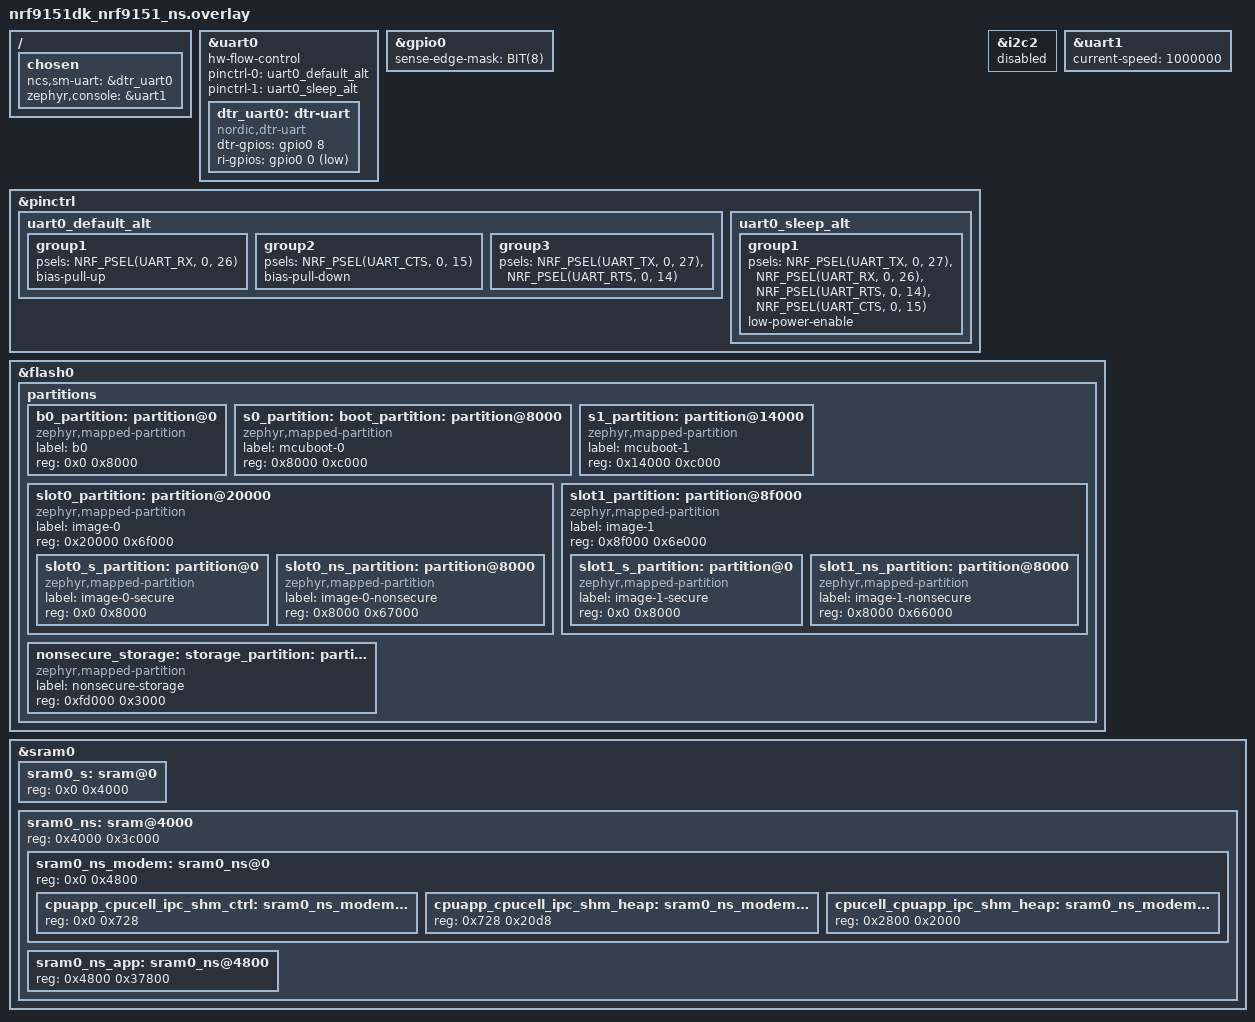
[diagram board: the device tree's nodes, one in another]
/*
 * Copyright (c) 2024 Nordic Semiconductor ASA
 *
 * SPDX-License-Identifier: LicenseRef-Nordic-5-Clause
 */

/ {
	chosen {
		ncs,sm-uart = &dtr_uart0;
		zephyr,console = &uart1;
	};
};

/* DTR with DK */
&uart0 {
	status = "okay";
	hw-flow-control;

	dtr_uart0: dtr-uart {
		compatible = "nordic,dtr-uart";
		dtr-gpios = <&gpio0 8 (GPIO_PULL_UP | GPIO_ACTIVE_HIGH)>;
		ri-gpios = <&gpio0 0 GPIO_ACTIVE_LOW>;
		status = "okay";
	};
	pinctrl-0 = <&uart0_default_alt>;
	pinctrl-1 = <&uart0_sleep_alt>;
	pinctrl-names = "default", "sleep";

};

&gpio0 {
	status = "okay";
	/* Use PORT event for DTR (8) pin to save power */
	sense-edge-mask = <BIT(8)>;
};


&pinctrl {
	uart0_default_alt: uart0_default_alt {
		group1 {
			psels = <NRF_PSEL(UART_RX, 0, 26)>;
			bias-pull-up;
		};
		group2 {
			psels = <NRF_PSEL(UART_CTS, 0, 15)>;
			bias-pull-down;
		};
		group3 {
			psels = <NRF_PSEL(UART_TX, 0, 27)>,
				<NRF_PSEL(UART_RTS, 0, 14)>;
		};
	};

	uart0_sleep_alt: uart0_sleep_alt {
		group1 {
			psels = <NRF_PSEL(UART_TX, 0, 27)>,
				<NRF_PSEL(UART_RX, 0, 26)>,
				<NRF_PSEL(UART_RTS, 0, 14)>,
				<NRF_PSEL(UART_CTS, 0, 15)>;
			low-power-enable;
		};
	};
};

/* Disable I2C2.
 * - Enabling IO expander causes ~20uA to be consumed while DTR is deasserted.
 * - We use P0.31 and P0.30 pins for DTR and RI signals with external MCU.
 */
&i2c2 {
	status = "disabled";
};

/* Enable UART1 as the shared backend for Zephyr logs and modem traces (VCOM1 on the DK).
 * Modem traces require 1 000 000 baud. Hardware flow control is not used.
 */
&uart1 {
	status = "okay";
	current-speed = <1000000>;
};

/*
 * Flash partition layout for nRF9151 DK (same with B0, MCUboot and application):
 *
 * 0x0000_0000  b0 (NSIB)                    ( 32 kB)
 * 0x0000_8000  s0 (MCUBoot image, slot 0)   ( 48 kB)
 * 0x0001_4000  s1 (MCUBoot image, slot 1)   ( 48 kB)
 * 0x0002_0000  slot0 (primary app)          (444 kB)
 *   0x0002_0000  TF-M secure                ( 32 kB)
 *   0x0002_8000  Application (non-secure)   (412 kB - (MCUBoot swap sector + MCUboot trailer))
 * 0x0008_f000  slot1 (secondary app)        (440 kB)
 * 0x000f_d000  Non-secure storage           ( 12 kB)
 */

/delete-node/ &boot_partition;
/delete-node/ &slot0_partition;
/delete-node/ &slot1_partition;
/delete-node/ &tfm_ps_partition;
/delete-node/ &tfm_its_partition;
/delete-node/ &tfm_otp_partition;
/delete-node/ &storage_partition;

&flash0 {
	partitions {
		b0_partition: partition@0 {
			compatible = "zephyr,mapped-partition";
			label = "b0";
			reg = <0x0 0x8000>;
		};

		s0_partition: boot_partition: partition@8000 {
			compatible = "zephyr,mapped-partition";
			label = "mcuboot-0";
			reg = <0x8000 0xc000>;
		};

		s1_partition: partition@14000 {
			compatible = "zephyr,mapped-partition";
			label = "mcuboot-1";
			reg = <0x14000 0xc000>;
		};

		slot0_partition: partition@20000 {
			compatible = "zephyr,mapped-partition";
			label = "image-0";
			reg = <0x20000 0x6f000>;
			ranges = <0x0 0x20000 0x6f000>;
			#address-cells = <1>;
			#size-cells = <1>;

			slot0_s_partition: partition@0 {
				compatible = "zephyr,mapped-partition";
				label = "image-0-secure";
				reg = <0x0 0x8000>;
			};

			slot0_ns_partition: partition@8000 {
				compatible = "zephyr,mapped-partition";
				label = "image-0-nonsecure";
				reg = <0x8000 0x67000>;
			};
		};

		slot1_partition: partition@8f000 {
			compatible = "zephyr,mapped-partition";
			label = "image-1";
			reg = <0x8f000 0x6e000>;
			ranges = <0x0 0x8f000 0x6e000>;
			#address-cells = <1>;
			#size-cells = <1>;

			slot1_s_partition: partition@0 {
				compatible = "zephyr,mapped-partition";
				label = "image-1-secure";
				reg = <0x0 0x8000>;
			};

			slot1_ns_partition: partition@8000 {
				compatible = "zephyr,mapped-partition";
				label = "image-1-nonsecure";
				reg = <0x8000 0x66000>;
			};
		};

		nonsecure_storage: storage_partition: partition@fd000 {
			compatible = "zephyr,mapped-partition";
			label = "nonsecure-storage";
			reg = <0xfd000 0x3000>;
		};
	};
};

/*
 * Application SRAM layout for nRF9151 DK:
 *
 * 0x2000_0000  Secure RAM                   (  16 kB)
 * 0x2000_4000  Non-secure RAM area          ( 240 kB)
 *   0x2000_4000  Modem shared area          (  34 kB)
 *     0x2000_4000  control                  (1832 B)
 *     0x2000_4728  app -> cell              (8408 B)
 *     0x2000_6800  cell -> app              (   8 kB)
 *   0x2000_8800  Application RAM            ( 222 kB)
 */

/delete-node/ &sram0_s;
/delete-node/ &sram0_ns;

&sram0 {

	sram0_s: sram@0 {
		reg = <0x0 0x4000>;
	};

	sram0_ns: sram@4000 {
		reg = <0x4000 0x3c000>;
		#address-cells = <1>;
		#size-cells = <1>;
		ranges = <0x0 0x4000 0x3c000>;

		/* Must be in first 128 kB of RAM. */
		sram0_ns_modem: sram0_ns@0 {
			/* Modem (shared) memory */
			reg = <0x0 0x4800>;
			#address-cells = <1>;
			#size-cells = <1>;
			ranges = <0x0 0x0 0x4800>;

			cpuapp_cpucell_ipc_shm_ctrl: sram0_ns_modem@0 {
				/* Modem IPC control */
				reg = <0x0 0x728>;
			};

			cpuapp_cpucell_ipc_shm_heap: sram0_ns_modem@728 {
				/* Modem IPC transmit */
				reg = <0x728 0x20d8>;
			};

			cpucell_cpuapp_ipc_shm_heap: sram0_ns_modem@2800 {
				/* Modem IPC receive */
				reg = <0x2800 0x2000>;
			};

		};

		sram0_ns_app: sram0_ns@4800 {
			/* Non-Secure application memory */
			reg = <0x4800 0x37800>;
		};
	};
};
